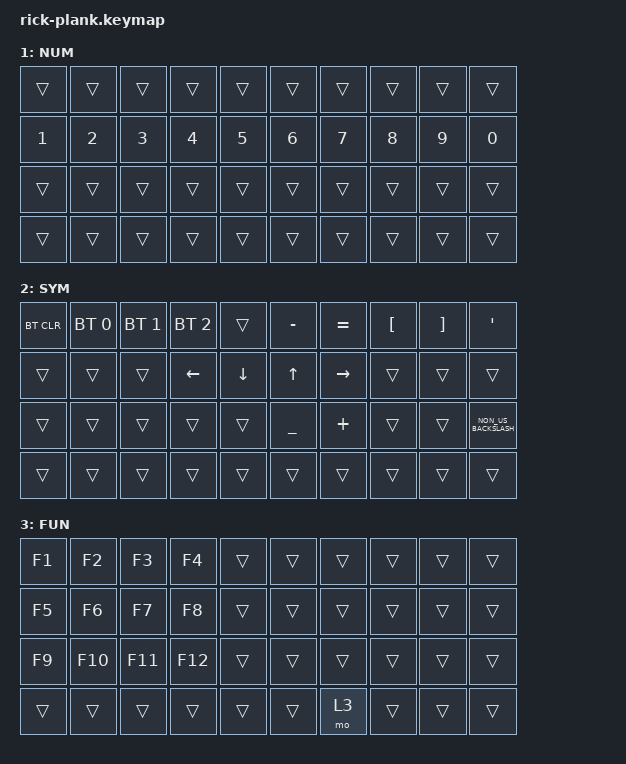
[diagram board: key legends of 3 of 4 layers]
#include <behaviors.dtsi>
#include <dt-bindings/zmk/keys.h>
#include <dt-bindings/zmk/bt.h>
#include <dt-bindings/zmk/mouse.h>
#include <behaviors/mouse_move.dtsi>
#include <behaviors/mouse_scroll.dtsi>

/ {
    behaviors {
        cmqus: comma_question {
            compatible = "zmk,behavior-mod-morph";
            label = "COMMA_QUESTION";
            #binding-cells = <0>;
            bindings = <&kp COMMA>, <&kp QUESTION>;

            mods = <(MOD_LSFT|MOD_RSFT)>;
        };

        dtsmi: dot_semi {
            compatible = "zmk,behavior-mod-morph";
            label = "DOT_SEMI";
            #binding-cells = <0>;
            bindings = <&kp DOT>, <&kp SEMI>;

            mods = <(MOD_LSFT|MOD_RSFT)>;
        };
        hm_rick: hmrick {
            compatible = "zmk,behavior-hold-tap";
            label = "HMRICK";
            bindings = <&kp>, <&kp>;

            #binding-cells = <2>;
            flavor = "tap-preferred";
            tapping-term-ms = <175>; // triggers the hold behavior when the tapping-term-ms has expired
            quick-tap-ms = <150>; // If you press a tapped hold-tap again within quick-tap-ms milliseconds of the first press, it will always trigger the tap behavior.
            require-prior-idle-ms = <185>; // like quick-tap-ms however it will apply for any non-modifier key pressed before it
        };

        as_ht: autoshift_hold_tap {
          compatible = "zmk,behavior-hold-tap";
          label = "AUTOSHIFT_HOLD_TAP";
          #binding-cells = <2>;
          tapping-term-ms = <200>;
          bindings = <&shifted>, <&kp>;
        };

        sticky: sticky {
            compatible = "zmk,behavior-sticky-key";
            label = "STICKY";
            bindings = <&kp>;
            #binding-cells = <1>;
            release-after-ms = <10000>;
        };
    };

macros {
    shifted: macro_shifted_kp {
      #binding-cells = <1>;
      label = "MACRO_SHIFTED_KP";
      compatible = "zmk,behavior-macro-one-param";
      bindings =
        <&macro_press &kp LSHFT>,
        <&macro_param_1to1 &macro_tap &kp MACRO_PLACEHOLDER>,
        <&macro_release &kp LSHFT>;
    };

    as: autoshift {
      compatible = "zmk,behavior-macro-one-param";
      #binding-cells = <1>;
      label = "AUTOSHIFT_KP";
      bindings =
        <&macro_press>,
        <&macro_param_1to1>,
        <&macro_param_1to2>,
        <&as_ht MACRO_PLACEHOLDER MACRO_PLACEHOLDER>,
        <&macro_pause_for_release>,
        <&macro_release>,
        <&macro_param_1to1>,
        <&macro_param_1to2>,
        <&as_ht MACRO_PLACEHOLDER MACRO_PLACEHOLDER>;
    };
  };
     keymap {
        compatible = "zmk,keymap";

        default_layer {
            display-name = "QWRT";
            bindings = <
                &bootloader   &kp W         &kp E         &kp R         &kp T                   &kp Y         &kp U         &kp I         &kp O         &kp P      
                &kp A         &kp S         &kp D         &kp F         &kp G                   &kp H         &kp J         &kp K         &kp L         &kp SEMI   
                &kp Z         &kp X         &kp C         &kp V         &kp B         &kp TAB   &kp LGUI      &kp N         &kp M         &kp COMMA     &kp DOT       &kp SLASH  
                &reset        &kp NUMBER_2  &kp ESC       &lt 2 SPACE   &kp BACKSPACE           &kp LSHIFT    &lt 1 ENTER   &kp NUMBER_8  &kp C_NEXT    &bootloader
            >;
        };

        num_layer {
            display-name = "NUM";
            bindings = <
                &trans        &trans        &trans        &trans        &trans                  &trans        &trans        &trans        &trans        &trans 
                &kp NUMBER_1  &kp NUMBER_2  &kp NUMBER_3  &kp NUMBER_4  &kp NUMBER_5            &kp NUMBER_6  &kp NUMBER_7  &kp NUMBER_8  &kp NUMBER_9  &kp NUMBER_0         
                &trans        &trans        &trans        &trans        &trans                  &trans        &trans        &trans        &trans        &trans         
                &trans        &trans        &trans        &trans        &trans                  &trans        &trans        &trans        &trans        &trans        
            >;
        };

        symbol_layer {
            display-name = "SYM";
            bindings = <
                &bt BT_CLR       &bt BT_SEL 0  &bt BT_SEL 1     &bt BT_SEL 2      &trans                &kp MINUS        &kp EQUAL      &kp LEFT_BRACKET   &kp RIGHT_BRACKET      &kp SQT               
                &trans           &trans        &trans           &kp LEFT          &kp DOWN              &kp UP           &kp RIGHT      &trans             &trans                 &trans 
                &trans           &trans        &trans           &trans            &trans                &kp UNDERSCORE   &kp PLUS       &trans             &trans                 &kp NON_US_BACKSLASH  
                &trans           &trans        &trans           &trans            &trans                &trans           &trans         &trans             &trans                 &trans                
            >;
        };

        function_layer {
            display-name = "FUN";
            bindings = <
                &kp F1   &kp F2    &kp F3    &kp F4    &trans                      &trans   &trans   &trans   &trans   &trans 
                &kp F5   &kp F6    &kp F7    &kp F8    &trans                      &trans   &trans   &trans   &trans   &trans 
                &kp F9   &kp F10   &kp F11   &kp F12   &trans                      &trans   &trans   &trans   &trans   &trans 
                &trans   &trans    &trans    &trans    &trans                      &trans   &mo 3    &trans   &trans   &trans
            >;
        };
    };
};
